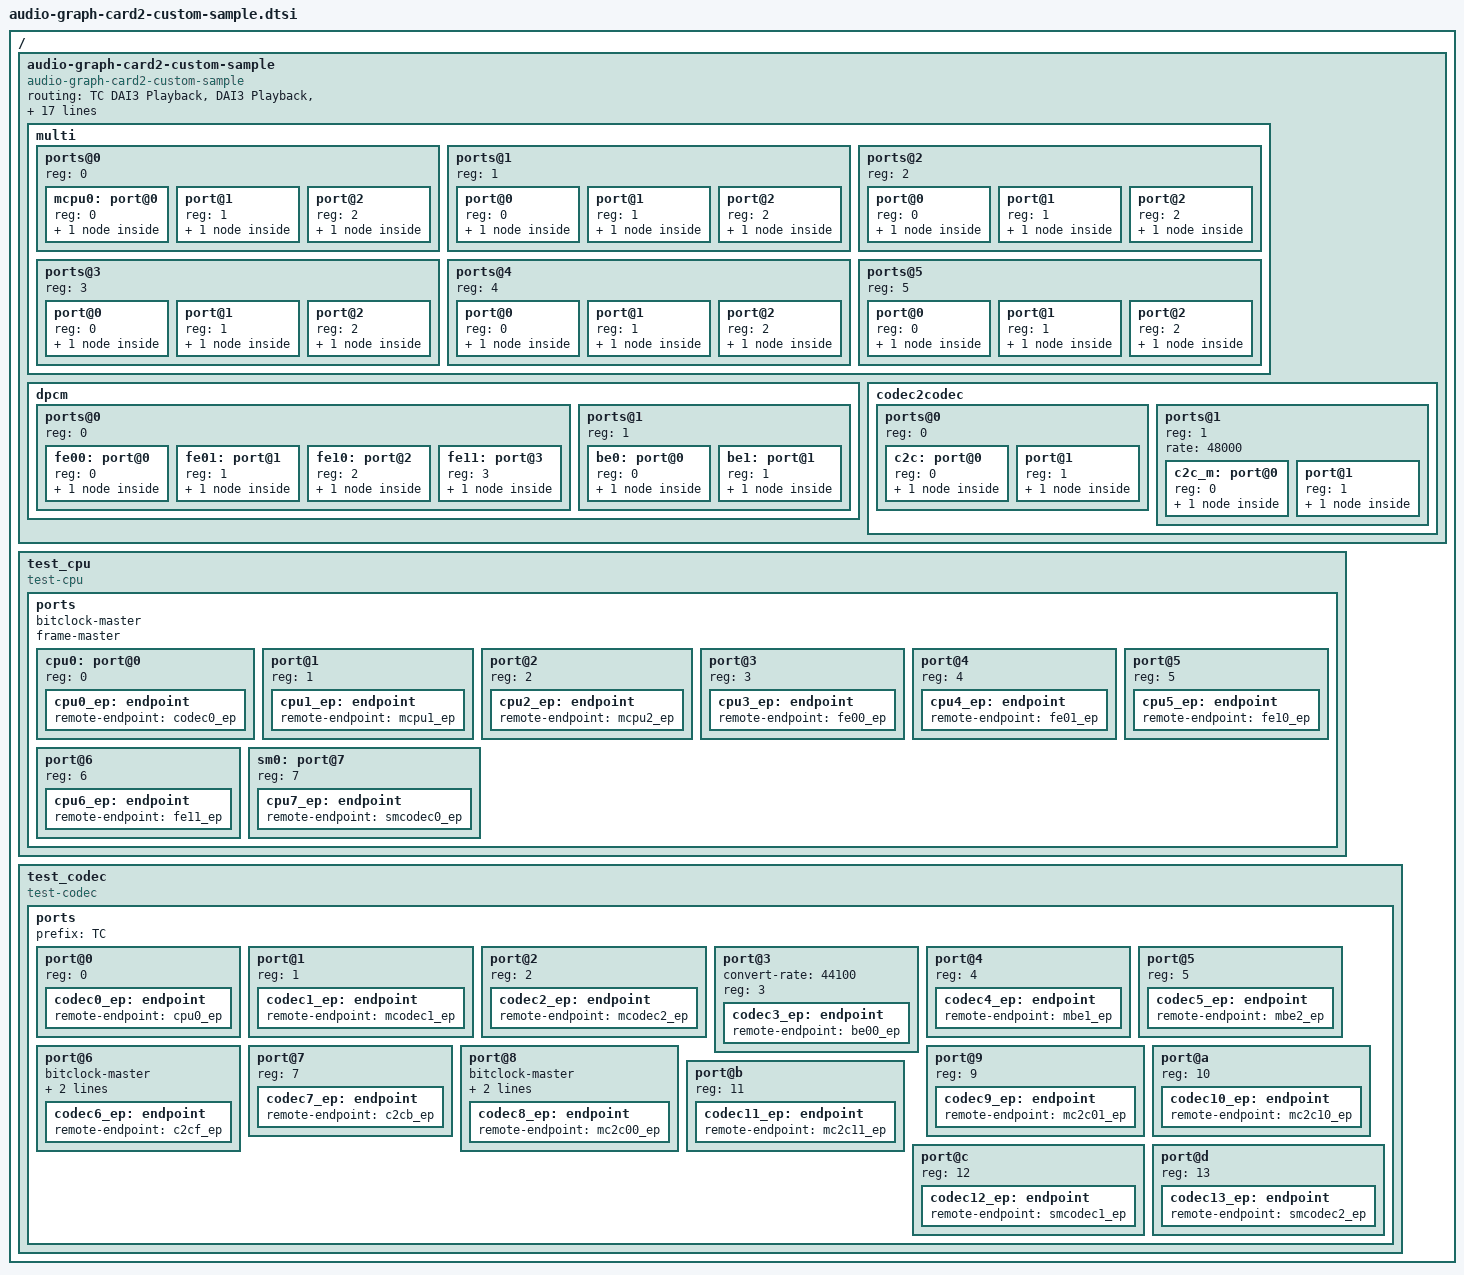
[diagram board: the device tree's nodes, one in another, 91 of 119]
/ {
	audio-graph-card2-custom-sample {
		compatible = "audio-graph-card2-custom-sample";
		routing = "TC DAI3 Playback",	"DAI3 Playback",
			  "TC DAI3 Playback",	"DAI4 Playback",
			  "DAI3 Capture",	"TC DAI3 Capture",
			  "DAI4 Capture",	"TC DAI3 Capture",
			  "TC DAI4 Playback",	"DAI5 Playback",
			  "TC DAI5 Playback",	"DAI5 Playback",
			  "TC DAI4 Playback",	"DAI6 Playback",
			  "TC DAI5 Playback",	"DAI6 Playback",
			  "DAI5 Capture",	"TC DAI4 Capture",
			  "DAI5 Capture",	"TC DAI5 Capture",
			  "DAI6 Capture",	"TC DAI4 Capture",
			  "DAI6 Capture",	"TC DAI5 Capture",
			  "TC OUT",		"TC DAI7 Playback",
			  "TC DAI6 Capture",	"TC IN",
			  "TC OUT",		"TC DAI10 Playback",
			  "TC DAI8 Capture",	"TC IN",
			  "TC OUT",		"TC DAI11 Playback",
			  "TC DAI9 Capture",	"TC IN";
		links = <
			 &cpu0
			&sm0
			 &mcpu0
			 &fe00 &fe01 &be0
			 &fe10 &fe11 &be1
			 &c2c
			 &c2c_m
		>;
		multi {
			#address-cells = <1>;
			#size-cells = <0>;
			ports@0 {
				reg = <0>;
				#address-cells = <1>;
				#size-cells = <0>;
			mcpu0:	port@0 { reg = <0>; mcpu0_ep: endpoint { remote-endpoint = <&mcodec0_ep>; }; };
				port@1 { reg = <1>; mcpu1_ep: endpoint { remote-endpoint = <&cpu1_ep>;    }; };
				port@2 { reg = <2>; mcpu2_ep: endpoint { remote-endpoint = <&cpu2_ep>;    }; };
			};
			ports@1 {
				reg = <1>;
				#address-cells = <1>;
				#size-cells = <0>;
				port@0 { reg = <0>; mcodec0_ep: endpoint { remote-endpoint = <&mcpu0_ep>;  }; };
				port@1 { reg = <1>; mcodec1_ep: endpoint { remote-endpoint = <&codec1_ep>; }; };
				port@2 { reg = <2>; mcodec2_ep: endpoint { remote-endpoint = <&codec2_ep>; }; };
			};
			ports@2 {
				reg = <2>;
				#address-cells = <1>;
				#size-cells = <0>;
				port@0 { reg = <0>; mbe_ep:  endpoint { remote-endpoint = <&be10_ep>;  }; };
				port@1 { reg = <1>; mbe1_ep: endpoint { remote-endpoint = <&codec4_ep>; }; };
				port@2 { reg = <2>; mbe2_ep: endpoint { remote-endpoint = <&codec5_ep>; }; };
			};
			ports@3 {
				reg = <3>;
				#address-cells = <1>;
				#size-cells = <0>;
				port@0 { reg = <0>; mc2c0_ep:  endpoint { remote-endpoint = <&c2cmf_ep>;  }; };
				port@1 { reg = <1>; mc2c00_ep: endpoint { remote-endpoint = <&codec8_ep>; }; };
				port@2 { reg = <2>; mc2c01_ep: endpoint { remote-endpoint = <&codec9_ep>; }; };
			};
			ports@4 {
				reg = <4>;
				#address-cells = <1>;
				#size-cells = <0>;
				port@0 { reg = <0>; mc2c1_ep:  endpoint { remote-endpoint = <&c2cmb_ep>;  }; };
				port@1 { reg = <1>; mc2c10_ep: endpoint { remote-endpoint = <&codec10_ep>; }; };
				port@2 { reg = <2>; mc2c11_ep: endpoint { remote-endpoint = <&codec11_ep>; }; };
			};
			ports@5 {
				reg = <5>;
				#address-cells = <1>;
				#size-cells = <0>;
				port@0 { reg = <0>; smcodec0_ep: endpoint { remote-endpoint = <&cpu7_ep>;    }; };
				port@1 { reg = <1>; smcodec1_ep: endpoint { remote-endpoint = <&codec12_ep>; }; };
				port@2 { reg = <2>; smcodec2_ep: endpoint { remote-endpoint = <&codec13_ep>; }; };
			};
		};
		dpcm {
			#address-cells = <1>;
			#size-cells = <0>;
			ports@0 {
				reg = <0>;
				#address-cells = <1>;
				#size-cells = <0>;
			fe00:	port@0 { reg = <0>; fe00_ep: endpoint { remote-endpoint = <&cpu3_ep>; }; };
			fe01:	port@1 { reg = <1>; fe01_ep: endpoint { remote-endpoint = <&cpu4_ep>; }; };
			fe10:	port@2 { reg = <2>; fe10_ep: endpoint { remote-endpoint = <&cpu5_ep>; }; };
			fe11:	port@3 { reg = <3>; fe11_ep: endpoint { remote-endpoint = <&cpu6_ep>; }; };
			};
			ports@1 {
				reg = <1>;
				#address-cells = <1>;
				#size-cells = <0>;
			be0:	port@0 { reg = <0>; be00_ep: endpoint { remote-endpoint = <&codec3_ep>; }; };
			be1:	port@1 { reg = <1>; be10_ep: endpoint { remote-endpoint = <&mbe_ep>; }; };
			};
		};
		codec2codec {
			#address-cells = <1>;
			#size-cells = <0>;
			ports@0 {
				reg = <0>;
				#address-cells = <1>;
				#size-cells = <0>;
			c2c:	port@0 { reg = <0>; c2cf_ep: endpoint { remote-endpoint = <&codec6_ep>; }; };
				port@1 { reg = <1>; c2cb_ep: endpoint { remote-endpoint = <&codec7_ep>; }; };
			};
			ports@1 {
				reg = <1>;
				#address-cells = <1>;
				#size-cells = <0>;
				rate = <48000>;
			c2c_m:	port@0 { reg = <0>; c2cmf_ep: endpoint { remote-endpoint = <&mc2c0_ep>; }; };
				port@1 { reg = <1>; c2cmb_ep: endpoint { remote-endpoint = <&mc2c1_ep>; }; };
			};
		};
	};
	test_cpu {
		compatible = "test-cpu";
		ports {
			#address-cells = <1>;
			#size-cells = <0>;
			bitclock-master;
			frame-master;
			cpu0: port@0 { reg = <0>; cpu0_ep: endpoint { remote-endpoint = <&codec0_ep>; }; };
			      port@1 { reg = <1>; cpu1_ep: endpoint { remote-endpoint = <&mcpu1_ep>; }; };
			      port@2 { reg = <2>; cpu2_ep: endpoint { remote-endpoint = <&mcpu2_ep>; }; };
			      port@3 { reg = <3>; cpu3_ep: endpoint { remote-endpoint = <&fe00_ep>; }; };
			      port@4 { reg = <4>; cpu4_ep: endpoint { remote-endpoint = <&fe01_ep>; }; };
			      port@5 { reg = <5>; cpu5_ep: endpoint { remote-endpoint = <&fe10_ep>; }; };
			      port@6 { reg = <6>; cpu6_ep: endpoint { remote-endpoint = <&fe11_ep>; }; };
			sm0:  port@7 { reg = <7>; cpu7_ep: endpoint { remote-endpoint = <&smcodec0_ep>; }; };
		};
	};
	test_codec {
		compatible = "test-codec";
		ports {
			#address-cells = <1>;
			#size-cells = <0>;
			prefix = "TC";
			port@0  { reg = <0>; codec0_ep:  endpoint { remote-endpoint = <&cpu0_ep>; }; };
			port@1  { reg = <1>; codec1_ep:  endpoint { remote-endpoint = <&mcodec1_ep>; }; };
			port@2  { reg = <2>; codec2_ep:  endpoint { remote-endpoint = <&mcodec2_ep>; }; };
			port@3  {
				convert-rate = <44100>;
				reg = <3>; codec3_ep:  endpoint { remote-endpoint = <&be00_ep>; };
			};
			port@4  { reg = <4>; codec4_ep:  endpoint { remote-endpoint = <&mbe1_ep>; }; };
			port@5  { reg = <5>; codec5_ep:  endpoint { remote-endpoint = <&mbe2_ep>; }; };
			port@6  { bitclock-master;
				  frame-master;
				  reg = <6>; codec6_ep:  endpoint { remote-endpoint = <&c2cf_ep>; }; };
			port@7  { reg = <7>; codec7_ep:  endpoint { remote-endpoint = <&c2cb_ep>; }; };
			port@8  { bitclock-master;
				  frame-master;
				  reg = <8>;  codec8_ep:  endpoint { remote-endpoint = <&mc2c00_ep>; }; };
			port@9  { reg = <9>;  codec9_ep:  endpoint { remote-endpoint = <&mc2c01_ep>; }; };
			port@a  { reg = <10>; codec10_ep: endpoint { remote-endpoint = <&mc2c10_ep>; }; };
			port@b  { reg = <11>; codec11_ep: endpoint { remote-endpoint = <&mc2c11_ep>; }; };
			port@c { reg = <12>; codec12_ep: endpoint { remote-endpoint = <&smcodec1_ep>; }; };
			port@d { reg = <13>; codec13_ep: endpoint { remote-endpoint = <&smcodec2_ep>; }; };
		};
	};
};
